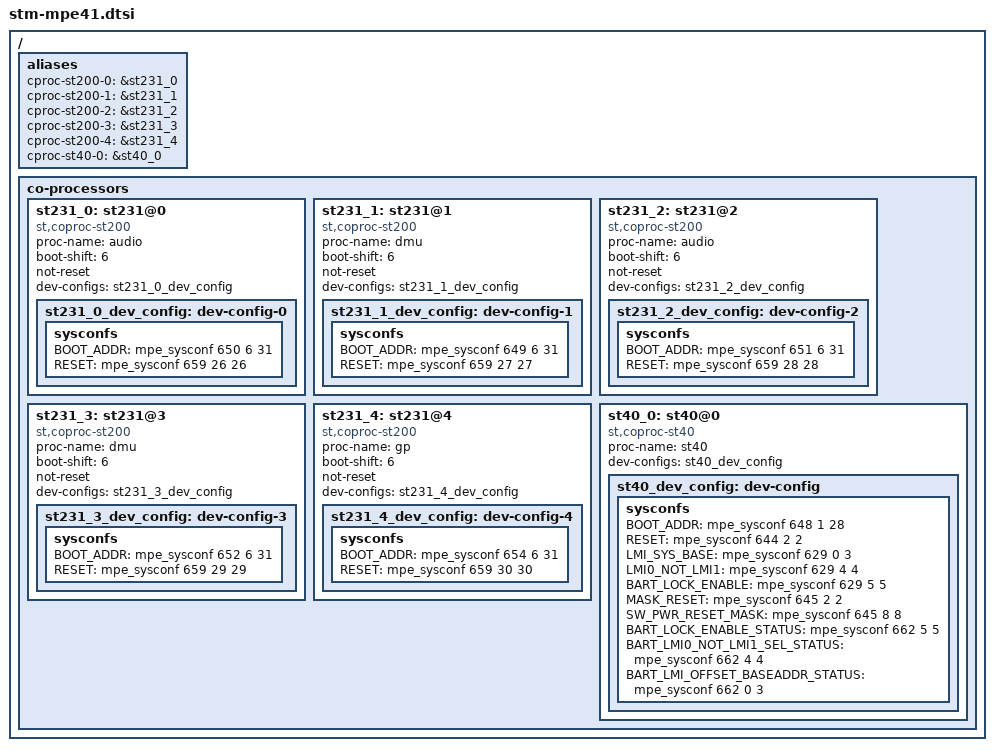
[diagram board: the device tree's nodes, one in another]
/*
 * Copyright (C) 2011 STMicroelectronics Limited.
 * Author: Srinivas Kandagatla <srinivas.kandagatla@st.com>
 *
 * This program is free software; you can redistribute it and/or modify
 * it under the terms of the GNU General Public License version 2 as
 * publishhed by the Free Software Foundation.
 */

/ {

	aliases {
		cproc-st200-0 = &st231_0;
		cproc-st200-1 = &st231_1;
		cproc-st200-2 = &st231_2;
		cproc-st200-3 = &st231_3;
		cproc-st200-4 = &st231_4;
		cproc-st40-0 = &st40_0;

	};

	co-processors{
		st231_0: st231@0{
			compatible	= "st,coproc-st200", "simple-bus";
			proc-name = "audio";
			boot-shift = <6>;
			not-reset;
			dev-configs = <&st231_0_dev_config>;

			st231_0_dev_config: dev-config-0 {
				#stm-sysconf-cells = <4>;
				sysconfs{
					BOOT_ADDR = <&mpe_sysconf 650 6 31>;
					RESET = <&mpe_sysconf 659 26  26>;
				};
			};
		};

		st231_1: st231@1{
			compatible	= "st,coproc-st200", "simple-bus";
			proc-name = "dmu";
			boot-shift = <6>;
			not-reset;
			dev-configs = <&st231_1_dev_config>;

			st231_1_dev_config: dev-config-1 {
				#stm-sysconf-cells = <4>;
				sysconfs{
					BOOT_ADDR = <&mpe_sysconf 649 6 31>;
					RESET = <&mpe_sysconf 659 27 27>;
				};
			};
		};

		st231_2: st231@2{
			compatible	= "st,coproc-st200", "simple-bus";
			proc-name = "audio";
			boot-shift = <6>;
			not-reset;
			dev-configs = <&st231_2_dev_config>;

			st231_2_dev_config: dev-config-2 {
				#stm-sysconf-cells = <4>;
				sysconfs{
					BOOT_ADDR = <&mpe_sysconf 651 6 31>;
					RESET = <&mpe_sysconf 659 28 28>;
				};
			};
		};

		st231_3: st231@3{
			compatible	= "st,coproc-st200", "simple-bus";
			proc-name = "dmu";
			boot-shift = <6>;
			not-reset;
			dev-configs = <&st231_3_dev_config>;

			st231_3_dev_config: dev-config-3 {
				#stm-sysconf-cells = <4>;
				sysconfs{
					BOOT_ADDR = <&mpe_sysconf 652 6 31>;
					RESET = <&mpe_sysconf 659 29 29>;
				};
			};
		};

		st231_4: st231@4{
			compatible	= "st,coproc-st200", "simple-bus";
			proc-name = "gp";
			boot-shift = <6>;
			not-reset;
			dev-configs = <&st231_4_dev_config>;

			st231_4_dev_config: dev-config-4 {
				#stm-sysconf-cells = <4>;
				sysconfs{
					BOOT_ADDR = <&mpe_sysconf 654 6 31>;
					RESET = <&mpe_sysconf 659 30 30>;
				};
			};
		};

		st40_0: st40@0{
			compatible	= "st,coproc-st40", "simple-bus";
			proc-name = "st40";
			dev-configs = <&st40_dev_config>;

			st40_dev_config: dev-config {
				#stm-sysconf-cells = <4>;
				sysconfs{
					BOOT_ADDR	=	<&mpe_sysconf 648 1 28>;
					RESET		=	<&mpe_sysconf 644 2 2>;
					LMI_SYS_BASE	=	<&mpe_sysconf 629 0 3>;
					LMI0_NOT_LMI1	=	<&mpe_sysconf 629 4 4>;
					BART_LOCK_ENABLE=	<&mpe_sysconf 629 5 5>;
					MASK_RESET	=	<&mpe_sysconf 645 2 2>;
					SW_PWR_RESET_MASK =	<&mpe_sysconf 645 8 8>;
					BART_LOCK_ENABLE_STATUS	=	<&mpe_sysconf 662 5 5>;
					BART_LMI0_NOT_LMI1_SEL_STATUS	=	<&mpe_sysconf 662 4 4>;
					BART_LMI_OFFSET_BASEADDR_STATUS	=	<&mpe_sysconf 662 0 3>;
				};
			};
		};
	};
};
